# ESP32-C2 register map
Vendor: ESPRESSIF SYSTEMS (SHANGHAI) CO., LTD.; Series: ESP32-C2; File version: 4
CPU: RV32IMC r0p0, little endian, no MPU, no FPU, 4 interrupt priority bits
Address unit: 32 bits
Registers are 32-bit, read-write, reset 0x0 unless marked. A register's access mark holds for its fields unless they carry their own. Offsets are from the block's base; [hi:lo] are bit positions; {n}, {i} and the like mark numbered series.

## ECC — ECC (ECC Hardware Accelerator)
Base 0x6003E000
0x0C MULT_INT_RAW ro — I2S interrupt raw register, valid in level.
  [0] CALC_DONE_INT_RAW — The raw interrupt status bit for the i2s_tx_hung_int interrupt
0x10 MULT_INT_ST ro — I2S interrupt status register.
  [0] CALC_DONE_INT_ST — The masked interrupt status bit for the i2s_rx_done_int interrupt
0x14 MULT_INT_ENA — I2S interrupt enable register.
  [0] CALC_DONE_INT_ENA — The interrupt enable bit for the i2s_rx_done_int interrupt
0x18 MULT_INT_CLR wo — I2S interrupt clear register.
  [0] CALC_DONE_INT_CLR — Set this bit to clear the i2s_rx_done_int interrupt
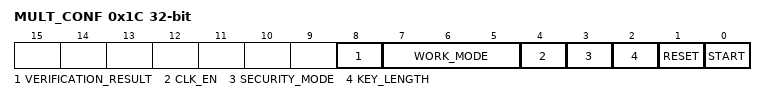
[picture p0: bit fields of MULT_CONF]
0x1C MULT_CONF access per field — I2S RX configure register
  [8] VERIFICATION_RESULT ro — Reserve
  [7:5] WORK_MODE rw — Reserved
  [4] CLK_EN rw — clk gate
  [3] SECURITY_MODE rw — Set this bit to enable slave receiver mode
  [2] KEY_LENGTH rw — Set this bit to start receiving data
  [1] RESET wo — Set this bit to reset Rx AFIFO
  [0] START rw — Set this bit to reset receiver
0xFC MULT_DATE reset 0x2012230 — Version control register
  [27:0] DATE — ECC mult version control register

## IO_MUX — Input/Output Multiplexer
Base 0x60009000
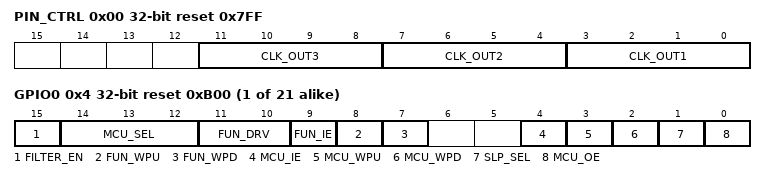
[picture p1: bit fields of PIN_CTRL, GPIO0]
0x00 PIN_CTRL reset 0x7FF — Clock Output Configuration Register
  [11:8] CLK_OUT3 — If you want to output clock for I2S to CLK_OUT_out3, set this register to 0x0. CLK_OUT_out3 can be found in peripheral output signals.
  [7:4] CLK_OUT2 — If you want to output clock for I2S to CLK_OUT_out2, set this register to 0x0. CLK_OUT_out2 can be found in peripheral output signals.
  [3:0] CLK_OUT1 — If you want to output clock for I2S to CLK_OUT_out1, set this register to 0x0. CLK_OUT_out1 can be found in peripheral output signals.
{0x4+4i} GPIO{i} (i=0..20) reset 0xB00 — IO MUX Configure Register for pad XTAL_32K_P
  [15] FILTER_EN — Enable filter for pin input signals. 1: Filter enabled; 2: Filter disabled.
  [14:12] MCU_SEL — Select IO MUX function for this signal. 0: Select Function 1; 1: Select Function 2; etc.
  [11:10] FUN_DRV — Select the drive strength of the pad. 0: ~5 mA; 1: ~10mA; 2: ~20mA; 3: ~40mA.
  [9] FUN_IE — Input enable of the pad. 1: input enabled; 0: input disabled.
  [8] FUN_WPU — Pull-up enable of the pad. 1: internal pull-up enabled; 0: internal pull-up disabled.
  [7] FUN_WPD — Pull-down enable of the pad. 1: internal pull-down enabled; 0: internal pull-down disabled.
  [4] MCU_IE — Input enable of the pad during sleep mode. 1: input enabled; 0: input disabled.
  [3] MCU_WPU — Pull-up enable of the pad during sleep mode. 1: internal pull-up enabled; 0: internal pull-up disabled.
  [2] MCU_WPD — Pull-down enable of the pad in sleep mode. 1: internal pull-down enabled; 0: internal pull-down disabled.
  [1] SLP_SEL — Sleep mode selection of this pad. Set to 1 to put the pad in pad mode.
  [0] MCU_OE — Output enable of the pad in sleep mode. 1: output enabled; 0: output disabled.
0xFC DATE reset 0x2106190 — IO MUX Version Control Register
  [27:0] REG_DATE — Version control register

## RNG — Hardware random number generator
Base 0x60026000
0xB0 DATA access not given — Random number data

## SENSITIVE
Base 0x600C1000
0x00 ROM_TABLE_LOCK — register description
  [0] ROM_TABLE_LOCK — Need add description
0x04 ROM_TABLE — register description
  [31:0] ROM_TABLE — Need add description
0x08 APB_PERIPHERAL_ACCESS_0 — register description
  [0] APB_PERIPHERAL_ACCESS_LOCK — Need add description
0x0C APB_PERIPHERAL_ACCESS_1 reset 0x1 — register description
  [0] APB_PERIPHERAL_ACCESS_SPLIT_BURST — Need add description
0x10 INTERNAL_SRAM_USAGE_0 — register description
  [0] INTERNAL_SRAM_USAGE_LOCK — Need add description
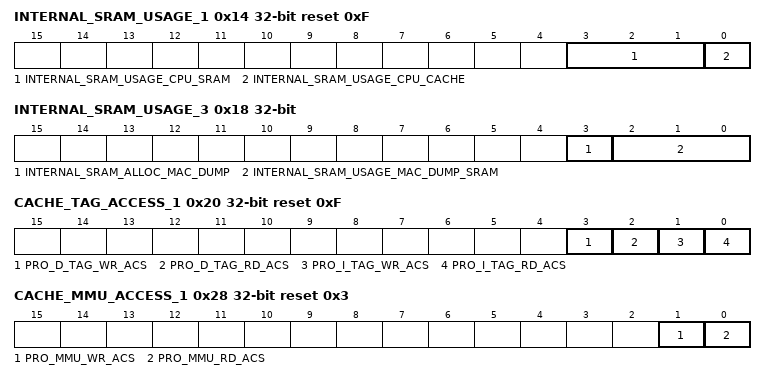
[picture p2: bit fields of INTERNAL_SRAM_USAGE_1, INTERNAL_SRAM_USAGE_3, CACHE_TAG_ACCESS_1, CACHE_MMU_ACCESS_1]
0x14 INTERNAL_SRAM_USAGE_1 reset 0xF — register description
  [3:1] INTERNAL_SRAM_USAGE_CPU_SRAM — Need add description
  [0] INTERNAL_SRAM_USAGE_CPU_CACHE — Need add description
0x18 INTERNAL_SRAM_USAGE_3 — register description
  [3] INTERNAL_SRAM_ALLOC_MAC_DUMP — Need add description
  [2:0] INTERNAL_SRAM_USAGE_MAC_DUMP_SRAM — Need add description
0x1C CACHE_TAG_ACCESS_0 — register description
  [0] CACHE_TAG_ACCESS_LOCK — Need add description
0x20 CACHE_TAG_ACCESS_1 reset 0xF — register description
  [3] PRO_D_TAG_WR_ACS — Need add description
  [2] PRO_D_TAG_RD_ACS — Need add description
  [1] PRO_I_TAG_WR_ACS — Need add description
  [0] PRO_I_TAG_RD_ACS — Need add description
0x24 CACHE_MMU_ACCESS_0 — register description
  [0] CACHE_MMU_ACCESS_LOCK — Need add description
0x28 CACHE_MMU_ACCESS_1 reset 0x3 — register description
  [1] PRO_MMU_WR_ACS — Need add description
  [0] PRO_MMU_RD_ACS — Need add description
0x2C PIF_ACCESS_MONITOR_0 — register description
  [0] PIF_ACCESS_MONITOR_LOCK — Need add description
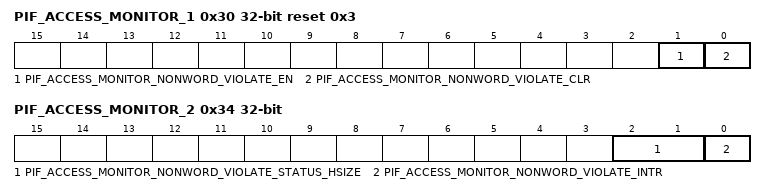
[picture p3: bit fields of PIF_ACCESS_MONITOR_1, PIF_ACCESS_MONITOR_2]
0x30 PIF_ACCESS_MONITOR_1 reset 0x3 — register description
  [1] PIF_ACCESS_MONITOR_NONWORD_VIOLATE_EN — Need add description
  [0] PIF_ACCESS_MONITOR_NONWORD_VIOLATE_CLR — Need add description
0x34 PIF_ACCESS_MONITOR_2 ro — register description
  [2:1] PIF_ACCESS_MONITOR_NONWORD_VIOLATE_STATUS_HSIZE — Need add description
  [0] PIF_ACCESS_MONITOR_NONWORD_VIOLATE_INTR — Need add description
0x38 PIF_ACCESS_MONITOR_3 ro — register description
  [31:0] PIF_ACCESS_MONITOR_NONWORD_VIOLATE_STATUS_HADDR — Need add description
0x3C XTS_AES_KEY_UPDATE — register description
  [0] XTS_AES_KEY_UPDATE — Set this bit to update xts_aes key
0x40 CLOCK_GATE reset 0x1 — register description
  [0] CLK_EN — Need add description
0xFFC SENSITIVE_REG_DATE reset 0x2106301 — register description
  [27:0] SENSITIVE_REG_DATE — Need add description

## SHA — SHA (Secure Hash Algorithm) Accelerator
Base 0x6003B000
0x00 MODE — Initial configuration register.
  [2:0] MODE — Sha mode.
0x04 T_STRING — SHA 512/t configuration register 0.
  [31:0] T_STRING — Sha t_string (used if and only if mode == SHA_512/t).
0x08 T_LENGTH — SHA 512/t configuration register 1.
  [5:0] T_LENGTH — Sha t_length (used if and only if mode == SHA_512/t).
0x0C DMA_BLOCK_NUM — DMA configuration register 0.
  [5:0] DMA_BLOCK_NUM — Dma-sha block number.
0x10 START ro — Typical SHA configuration register 0.
  [31:1] START — Reserved.
0x14 CONTINUE ro — Typical SHA configuration register 1.
  [31:1] CONTINUE — Reserved.
0x18 BUSY ro
  [0] STATE — Sha busy state. 1'b0: idle. 1'b1: busy.
0x1C DMA_START wo — DMA configuration register 1.
  [0] DMA_START — Start dma-sha.
0x20 DMA_CONTINUE wo — DMA configuration register 2.
  [0] DMA_CONTINUE — Continue dma-sha.
0x24 CLEAR_IRQ wo — Interrupt clear register.
  [0] CLEAR_INTERRUPT — Clear sha interrupt.
0x28 IRQ_ENA — Interrupt enable register.
  [0] INTERRUPT_ENA — Sha interrupt enable register. 1'b0: disable(default). 1'b1: enable.
0x2C DATE reset 0x20200616
  [29:0] DATE — Sha date information/ sha version information.
{0x40+i} H_MEM[{i}] (i=0..63) 8-bit access not given — Sha H memory which contains intermediate hash or finial hash.
{0x80+i} M_MEM[{i}] (i=0..63) 8-bit access not given — Sha M memory which contains message.

## XTS_AES — XTS-AES-128 Flash Encryption
Base 0x600CC000
{0x0+i} PLAIN_MEM[{i}] (i=0..15) 8-bit access not given — The memory that stores plaintext
0x40 LINESIZE — XTS-AES line-size register
  [0] LINESIZE — This bit stores the line size parameter. 0: 16Byte, 1: 32Byte.
0x44 DESTINATION — XTS-AES destination register
  [0] DESTINATION — This bit stores the destination. 0: flash(default). 1: reserved.
0x48 PHYSICAL_ADDRESS — XTS-AES physical address register
  [29:0] PHYSICAL_ADDRESS — Those bits stores the physical address. If linesize is 16-byte, the physical address should be aligned of 16 bytes. If linesize is 32-byte, the physical address should be aligned of 32 bytes.
0x4C TRIGGER wo — XTS-AES trigger register
  [0] TRIGGER — Set this bit to start manual encryption calculation
0x50 RELEASE wo — XTS-AES release register
  [0] RELEASE — Set this bit to release the manual encrypted result, after that the result will be visible to spi
0x54 DESTROY wo — XTS-AES destroy register
  [0] DESTROY — Set this bit to destroy XTS-AES result.
0x58 STATE ro — XTS-AES status register
  [1:0] STATE — Those bits shows XTS-AES status. 0=IDLE, 1=WORK, 2=RELEASE, 3=USE. IDLE means that XTS-AES is idle. WORK means that XTS-AES is busy with calculation. RELEASE means the encrypted result is generated but not visible to mspi. USE means that the encrypted result is visible to mspi.
0x5C DATE reset 0x20200623 — XTS-AES version control register
  [29:0] DATE — Those bits stores the version information of XTS-AES.
